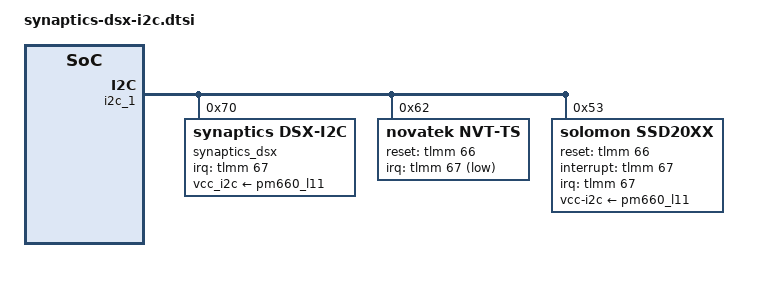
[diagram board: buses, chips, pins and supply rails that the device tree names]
/* Copyright (c) 2016-2018, The Linux Foundation. All rights reserved.
 *
 * This program is free software; you can redistribute it and/or modify
 * it under the terms of the GNU General Public License version 2 and
 * only version 2 as published by the Free Software Foundation.
 *
 * This program is distributed in the hope that it will be useful,
 * but WITHOUT ANY WARRANTY; without even the implied warranty of
 * MERCHANTABILITY or FITNESS FOR A PARTICULAR PURPOSE.  See the
 * GNU General Public License for more details.
 */

&i2c_1{
	status = "ok";
	synaptics_dsx@70 {
		compatible = "synaptics,dsx-i2c";
		reg = <0x70>;
		interrupt-parent = <&tlmm>;
		interrupts = <67 0x2008>;
		vcc_i2c-supply= <&pm660_l11>;
		pinctrl-names = "pmx_ts_active", "pmx_ts_suspend";
		pinctrl-0 = <&ts_active>;
		pinctrl-1 = <&ts_int_suspend &ts_reset_suspend>;
		synaptics,ub-i2c-addr = <0x2c>;
		synaptics,irq-gpio = <&tlmm 67 0x2008>; /* IRQF_ONESHOT | IRQF_TRIGGER_LOW */
		synaptics,irq-on-state = <0>;
		synaptics,power-delay-ms = <200>;
		synaptics,reset-delay-ms = <200>;
		synaptics,reset-on-state = <0>;
		synaptics,reset-active-ms = <20>;
		/* uncomment and update line below as appropriate if there are 0D buttons */
		synaptics,cap-button-codes = <139 172 158>;
	};

	/* Novatek device tree node */
	novatek@62 {
		compatible = "novatek,NVT-ts";
		reg = <0x62>;
		status = "ok";

		novatek,reset-gpio = <&tlmm 66 0x00>;
		novatek,irq-gpio = <&tlmm 67 0x2001>;

		/* MP Config*/
		IC_X_CFG_SIZE = <18>;
		IC_Y_CFG_SIZE = <32>;
		IC_KEY_CFG_SIZE = <4>;
		X_Channel = <18>;
		Y_Channel = <32>;
		AIN_X = <17 16 15 14 13 12 11 10 9 8 7 6 5 4 3 2 1 0>;
		AIN_Y = <31 30 29 28 27 26 25 24 23 22 21 20 19 18 17 16 15 14 13 12 11 10 9 8 7 6 5 4 3 2 1 0>;
		AIN_KEY = <0 1 2 0xFF>;

		novatek-mp-criteria-nvtpid@0 {
			#address-cells = <1>;
			#size-cells = <0>;
			compatible = "novatek-mp-criteria-nvtpid";

			/* MP Criteria */
			PS_Config_Lmt_Short_Rawdata_P = <
				20000 20000 20000 20000 20000 20000 20000 20000 20000 20000 20000 20000 20000 20000 20000 20000 20000 20000
				20000 20000 20000 20000 20000 20000 20000 20000 20000 20000 20000 20000 20000 20000 20000 20000 20000 20000
				20000 20000 20000 20000 20000 20000 20000 20000 20000 20000 20000 20000 20000 20000 20000 20000 20000 20000
				20000 20000 20000 20000 20000 20000 20000 20000 20000 20000 20000 20000 20000 20000 20000 20000 20000 20000
				20000 20000 20000 20000 20000 20000 20000 20000 20000 20000 20000 20000 20000 20000 20000 20000 20000 20000
				20000 20000 20000 20000 20000 20000 20000 20000 20000 20000 20000 20000 20000 20000 20000 20000 20000 20000
				20000 20000 20000 20000 20000 20000 20000 20000 20000 20000 20000 20000 20000 20000 20000 20000 20000 20000
				20000 20000 20000 20000 20000 20000 20000 20000 20000 20000 20000 20000 20000 20000 20000 20000 20000 20000
				20000 20000 20000 20000 20000 20000 20000 20000 20000 20000 20000 20000 20000 20000 20000 20000 20000 20000
				20000 20000 20000 20000 20000 20000 20000 20000 20000 20000 20000 20000 20000 20000 20000 20000 20000 20000
				20000 20000 20000 20000 20000 20000 20000 20000 20000 20000 20000 20000 20000 20000 20000 20000 20000 20000
				20000 20000 20000 20000 20000 20000 20000 20000 20000 20000 20000 20000 20000 20000 20000 20000 20000 20000
				20000 20000 20000 20000 20000 20000 20000 20000 20000 20000 20000 20000 20000 20000 20000 20000 20000 20000
				20000 20000 20000 20000 20000 20000 20000 20000 20000 20000 20000 20000 20000 20000 20000 20000 20000 20000
				20000 20000 20000 20000 20000 20000 20000 20000 20000 20000 20000 20000 20000 20000 20000 20000 20000 20000
				20000 20000 20000 20000 20000 20000 20000 20000 20000 20000 20000 20000 20000 20000 20000 20000 20000 20000
				20000 20000 20000 20000 20000 20000 20000 20000 20000 20000 20000 20000 20000 20000 20000 20000 20000 20000
				20000 20000 20000 20000 20000 20000 20000 20000 20000 20000 20000 20000 20000 20000 20000 20000 20000 20000
				20000 20000 20000 20000 20000 20000 20000 20000 20000 20000 20000 20000 20000 20000 20000 20000 20000 20000
				20000 20000 20000 20000 20000 20000 20000 20000 20000 20000 20000 20000 20000 20000 20000 20000 20000 20000
				20000 20000 20000 20000 20000 20000 20000 20000 20000 20000 20000 20000 20000 20000 20000 20000 20000 20000
				20000 20000 20000 20000 20000 20000 20000 20000 20000 20000 20000 20000 20000 20000 20000 20000 20000 20000
				20000 20000 20000 20000 20000 20000 20000 20000 20000 20000 20000 20000 20000 20000 20000 20000 20000 20000
				20000 20000 20000 20000 20000 20000 20000 20000 20000 20000 20000 20000 20000 20000 20000 20000 20000 20000
				20000 20000 20000 20000 20000 20000 20000 20000 20000 20000 20000 20000 20000 20000 20000 20000 20000 20000
				20000 20000 20000 20000 20000 20000 20000 20000 20000 20000 20000 20000 20000 20000 20000 20000 20000 20000
				20000 20000 20000 20000 20000 20000 20000 20000 20000 20000 20000 20000 20000 20000 20000 20000 20000 20000
				20000 20000 20000 20000 20000 20000 20000 20000 20000 20000 20000 20000 20000 20000 20000 20000 20000 20000
				20000 20000 20000 20000 20000 20000 20000 20000 20000 20000 20000 20000 20000 20000 20000 20000 20000 20000
				20000 20000 20000 20000 20000 20000 20000 20000 20000 20000 20000 20000 20000 20000 20000 20000 20000 20000
				20000 20000 20000 20000 20000 20000 20000 20000 20000 20000 20000 20000 20000 20000 20000 20000 20000 20000
				20000 20000 20000 20000 20000 20000 20000 20000 20000 20000 20000 20000 20000 20000 20000 20000 20000 20000
				20000 20000 20000>;

			PS_Config_Lmt_Short_Rawdata_N = <
				11550 11550 11550 11550 11550 11550 11550 11550 11550 11550 11550 11550 11550 11550 11550 11550 11550 11550
				11550 11550 11550 11550 11550 11550 11550 11550 11550 11550 11550 11550 11550 11550 11550 11550 11550 11550
				11550 11550 11550 11550 11550 11550 11550 11550 11550 11550 11550 11550 11550 11550 11550 11550 11550 11550
				11550 11550 11550 11550 11550 11550 11550 11550 11550 11550 11550 11550 11550 11550 11550 11550 11550 11550
				11550 11550 11550 11550 11550 11550 11550 11550 11550 11550 11550 11550 11550 11550 11550 11550 11550 11550
				11550 11550 11550 11550 11550 11550 11550 11550 11550 11550 11550 11550 11550 11550 11550 11550 11550 11550
				11550 11550 11550 11550 11550 11550 11550 11550 11550 11550 11550 11550 11550 11550 11550 11550 11550 11550
				11550 11550 11550 11550 11550 11550 11550 11550 11550 11550 11550 11550 11550 11550 11550 11550 11550 11550
				11550 11550 11550 11550 11550 11550 11550 11550 11550 11550 11550 11550 11550 11550 11550 11550 11550 11550
				11550 11550 11550 11550 11550 11550 11550 11550 11550 11550 11550 11550 11550 11550 11550 11550 11550 11550
				11550 11550 11550 11550 11550 11550 11550 11550 11550 11550 11550 11550 11550 11550 11550 11550 11550 11550
				11550 11550 11550 11550 11550 11550 11550 11550 11550 11550 11550 11550 11550 11550 11550 11550 11550 11550
				11550 11550 11550 11550 11550 11550 11550 11550 11550 11550 11550 11550 11550 11550 11550 11550 11550 11550
				11550 11550 11550 11550 11550 11550 11550 11550 11550 11550 11550 11550 11550 11550 11550 11550 11550 11550
				11550 11550 11550 11550 11550 11550 11550 11550 11550 11550 11550 11550 11550 11550 11550 11550 11550 11550
				11550 11550 11550 11550 11550 11550 11550 11550 11550 11550 11550 11550 11550 11550 11550 11550 11550 11550
				11550 11550 11550 11550 11550 11550 11550 11550 11550 11550 11550 11550 11550 11550 11550 11550 11550 11550
				11550 11550 11550 11550 11550 11550 11550 11550 11550 11550 11550 11550 11550 11550 11550 11550 11550 11550
				11550 11550 11550 11550 11550 11550 11550 11550 11550 11550 11550 11550 11550 11550 11550 11550 11550 11550
				11550 11550 11550 11550 11550 11550 11550 11550 11550 11550 11550 11550 11550 11550 11550 11550 11550 11550
				11550 11550 11550 11550 11550 11550 11550 11550 11550 11550 11550 11550 11550 11550 11550 11550 11550 11550
				11550 11550 11550 11550 11550 11550 11550 11550 11550 11550 11550 11550 11550 11550 11550 11550 11550 11550
				11550 11550 11550 11550 11550 11550 11550 11550 11550 11550 11550 11550 11550 11550 11550 11550 11550 11550
				11550 11550 11550 11550 11550 11550 11550 11550 11550 11550 11550 11550 11550 11550 11550 11550 11550 11550
				11550 11550 11550 11550 11550 11550 11550 11550 11550 11550 11550 11550 11550 11550 11550 11550 11550 11550
				11550 11550 11550 11550 11550 11550 11550 11550 11550 11550 11550 11550 11550 11550 11550 11550 11550 11550
				11550 11550 11550 11550 11550 11550 11550 11550 11550 11550 11550 11550 11550 11550 11550 11550 11550 11550
				11550 11550 11550 11550 11550 11550 11550 11550 11550 11550 11550 11550 11550 11550 11550 11550 11550 11550
				11550 11550 11550 11550 11550 11550 11550 11550 11550 11550 11550 11550 11550 11550 11550 11550 11550 11550
				11550 11550 11550 11550 11550 11550 11550 11550 11550 11550 11550 11550 11550 11550 11550 11550 11550 11550
				11550 11550 11550 11550 11550 11550 11550 11550 11550 11550 11550 11550 11550 11550 11550 11550 11550 11550
				11550 11550 11550 11550 11550 11550 11550 11550 11550 11550 11550 11550 11550 11550 11550 11550 11550 11550
				11550 11550 11550>;

			PS_Config_Lmt_Short_Diff_P = <
				6300 6300 6300 6300 6300 6300 6300 6300 6300 6300 6300 6300 6300 6300 6300 6300 6300 6300
				6300 6300 6300 6300 6300 6300 6300 6300 6300 6300 6300 6300 6300 6300 6300 6300 6300 6300
				6300 6300 6300 6300 6300 6300 6300 6300 6300 6300 6300 6300 6300 6300 6300 6300 6300 6300
				6300 6300 6300 6300 6300 6300 6300 6300 6300 6300 6300 6300 6300 6300 6300 6300 6300 6300
				6300 6300 6300 6300 6300 6300 6300 6300 6300 6300 6300 6300 6300 6300 6300 6300 6300 6300
				6300 6300 6300 6300 6300 6300 6300 6300 6300 6300 6300 6300 6300 6300 6300 6300 6300 6300
				6300 6300 6300 6300 6300 6300 6300 6300 6300 6300 6300 6300 6300 6300 6300 6300 6300 6300
				6300 6300 6300 6300 6300 6300 6300 6300 6300 6300 6300 6300 6300 6300 6300 6300 6300 6300
				6300 6300 6300 6300 6300 6300 6300 6300 6300 6300 6300 6300 6300 6300 6300 6300 6300 6300
				6300 6300 6300 6300 6300 6300 6300 6300 6300 6300 6300 6300 6300 6300 6300 6300 6300 6300
				6300 6300 6300 6300 6300 6300 6300 6300 6300 6300 6300 6300 6300 6300 6300 6300 6300 6300
				6300 6300 6300 6300 6300 6300 6300 6300 6300 6300 6300 6300 6300 6300 6300 6300 6300 6300
				6300 6300 6300 6300 6300 6300 6300 6300 6300 6300 6300 6300 6300 6300 6300 6300 6300 6300
				6300 6300 6300 6300 6300 6300 6300 6300 6300 6300 6300 6300 6300 6300 6300 6300 6300 6300
				6300 6300 6300 6300 6300 6300 6300 6300 6300 6300 6300 6300 6300 6300 6300 6300 6300 6300
				6300 6300 6300 6300 6300 6300 6300 6300 6300 6300 6300 6300 6300 6300 6300 6300 6300 6300
				6300 6300 6300 6300 6300 6300 6300 6300 6300 6300 6300 6300 6300 6300 6300 6300 6300 6300
				6300 6300 6300 6300 6300 6300 6300 6300 6300 6300 6300 6300 6300 6300 6300 6300 6300 6300
				6300 6300 6300 6300 6300 6300 6300 6300 6300 6300 6300 6300 6300 6300 6300 6300 6300 6300
				6300 6300 6300 6300 6300 6300 6300 6300 6300 6300 6300 6300 6300 6300 6300 6300 6300 6300
				6300 6300 6300 6300 6300 6300 6300 6300 6300 6300 6300 6300 6300 6300 6300 6300 6300 6300
				6300 6300 6300 6300 6300 6300 6300 6300 6300 6300 6300 6300 6300 6300 6300 6300 6300 6300
				6300 6300 6300 6300 6300 6300 6300 6300 6300 6300 6300 6300 6300 6300 6300 6300 6300 6300
				6300 6300 6300 6300 6300 6300 6300 6300 6300 6300 6300 6300 6300 6300 6300 6300 6300 6300
				6300 6300 6300 6300 6300 6300 6300 6300 6300 6300 6300 6300 6300 6300 6300 6300 6300 6300
				6300 6300 6300 6300 6300 6300 6300 6300 6300 6300 6300 6300 6300 6300 6300 6300 6300 6300
				6300 6300 6300 6300 6300 6300 6300 6300 6300 6300 6300 6300 6300 6300 6300 6300 6300 6300
				6300 6300 6300 6300 6300 6300 6300 6300 6300 6300 6300 6300 6300 6300 6300 6300 6300 6300
				6300 6300 6300 6300 6300 6300 6300 6300 6300 6300 6300 6300 6300 6300 6300 6300 6300 6300
				6300 6300 6300 6300 6300 6300 6300 6300 6300 6300 6300 6300 6300 6300 6300 6300 6300 6300
				6300 6300 6300 6300 6300 6300 6300 6300 6300 6300 6300 6300 6300 6300 6300 6300 6300 6300
				6300 6300 6300 6300 6300 6300 6300 6300 6300 6300 6300 6300 6300 6300 6300 6300 6300 6300
				6300 6300 6300>;

			PS_Config_Lmt_Short_Diff_N = <
				0 0 0 0 0 0 0 0 0 0 0 0 0 0 0 0 0
				0 0 0 0 0 0 0 0 0 0 0 0 0 0 0 0 0
				0 0 0 0 0 0 0 0 0 0 0 0 0 0 0 0 0
				0 0 0 0 0 0 0 0 0 0 0 0 0 0 0 0 0
				0 0 0 0 0 0 0 0 0 0 0 0 0 0 0 0 0
				0 0 0 0 0 0 0 0 0 0 0 0 0 0 0 0 0
				0 0 0 0 0 0 0 0 0 0 0 0 0 0 0 0 0
				0 0 0 0 0 0 0 0 0 0 0 0 0 0 0 0 0
				0 0 0 0 0 0 0 0 0 0 0 0 0 0 0 0 0
				0 0 0 0 0 0 0 0 0 0 0 0 0 0 0 0 0
				0 0 0 0 0 0 0 0 0 0 0 0 0 0 0 0 0
				0 0 0 0 0 0 0 0 0 0 0 0 0 0 0 0 0
				0 0 0 0 0 0 0 0 0 0 0 0 0 0 0 0 0
				0 0 0 0 0 0 0 0 0 0 0 0 0 0 0 0 0
				0 0 0 0 0 0 0 0 0 0 0 0 0 0 0 0 0
				0 0 0 0 0 0 0 0 0 0 0 0 0 0 0 0 0
				0 0 0 0 0 0 0 0 0 0 0 0 0 0 0 0 0
				0 0 0 0 0 0 0 0 0 0 0 0 0 0 0 0 0
				0 0 0 0 0 0 0 0 0 0 0 0 0 0 0 0 0
				0 0 0 0 0 0 0 0 0 0 0 0 0 0 0 0 0
				0 0 0 0 0 0 0 0 0 0 0 0 0 0 0 0 0
				0 0 0 0 0 0 0 0 0 0 0 0 0 0 0 0 0
				0 0 0 0 0 0 0 0 0 0 0 0 0 0 0 0 0
				0 0 0 0 0 0 0 0 0 0 0 0 0 0 0 0 0
				0 0 0 0 0 0 0 0 0 0 0 0 0 0 0 0 0
				0 0 0 0 0 0 0 0 0 0 0 0 0 0 0 0 0
				0 0 0 0 0 0 0 0 0 0 0 0 0 0 0 0 0
				0 0 0 0 0 0 0 0 0 0 0 0 0 0 0 0 0
				0 0 0 0 0 0 0 0 0 0 0 0 0 0 0 0 0
				0 0 0 0 0 0 0 0 0 0 0 0 0 0 0 0 0
				0 0 0 0 0 0 0 0 0 0 0 0 0 0 0 0 0
				0 0 0 0 0 0 0 0 0 0 0 0 0 0 0 0 0
				0 0 0 0 0 0 0 0 0 0 0 0 0 0 0 0 0
				0 0 0 0 0 0 0 0 0 0 0 0 0 0 0 0 0
				0>;

			PS_Config_Lmt_Short_Base_P = <
				2000 2000 2000 2000 2000 2000 2000 2000 2000 2000 2000 2000 2000 2000 2000 2000 2000 2000
				2000 2000 2000 2000 2000 2000 2000 2000 2000 2000 2000 2000 2000 2000 2000 2000 2000 2000
				2000 2000 2000 2000 2000 2000 2000 2000 2000 2000 2000 2000 2000 2000 2000 2000 2000 2000
				2000 2000 2000 2000 2000 2000 2000 2000 2000 2000 2000 2000 2000 2000 2000 2000 2000 2000
				2000 2000 2000 2000 2000 2000 2000 2000 2000 2000 2000 2000 2000 2000 2000 2000 2000 2000
				2000 2000 2000 2000 2000 2000 2000 2000 2000 2000 2000 2000 2000 2000 2000 2000 2000 2000
				2000 2000 2000 2000 2000 2000 2000 2000 2000 2000 2000 2000 2000 2000 2000 2000 2000 2000
				2000 2000 2000 2000 2000 2000 2000 2000 2000 2000 2000 2000 2000 2000 2000 2000 2000 2000
				2000 2000 2000 2000 2000 2000 2000 2000 2000 2000 2000 2000 2000 2000 2000 2000 2000 2000
				2000 2000 2000 2000 2000 2000 2000 2000 2000 2000 2000 2000 2000 2000 2000 2000 2000 2000
				2000 2000 2000 2000 2000 2000 2000 2000 2000 2000 2000 2000 2000 2000 2000 2000 2000 2000
				2000 2000 2000 2000 2000 2000 2000 2000 2000 2000 2000 2000 2000 2000 2000 2000 2000 2000
				2000 2000 2000 2000 2000 2000 2000 2000 2000 2000 2000 2000 2000 2000 2000 2000 2000 2000
				2000 2000 2000 2000 2000 2000 2000 2000 2000 2000 2000 2000 2000 2000 2000 2000 2000 2000
				2000 2000 2000 2000 2000 2000 2000 2000 2000 2000 2000 2000 2000 2000 2000 2000 2000 2000
				2000 2000 2000 2000 2000 2000 2000 2000 2000 2000 2000 2000 2000 2000 2000 2000 2000 2000
				2000 2000 2000 2000 2000 2000 2000 2000 2000 2000 2000 2000 2000 2000 2000 2000 2000 2000
				2000 2000 2000 2000 2000 2000 2000 2000 2000 2000 2000 2000 2000 2000 2000 2000 2000 2000
				2000 2000 2000 2000 2000 2000 2000 2000 2000 2000 2000 2000 2000 2000 2000 2000 2000 2000
				2000 2000 2000 2000 2000 2000 2000 2000 2000 2000 2000 2000 2000 2000 2000 2000 2000 2000
				2000 2000 2000 2000 2000 2000 2000 2000 2000 2000 2000 2000 2000 2000 2000 2000 2000 2000
				2000 2000 2000 2000 2000 2000 2000 2000 2000 2000 2000 2000 2000 2000 2000 2000 2000 2000
				2000 2000 2000 2000 2000 2000 2000 2000 2000 2000 2000 2000 2000 2000 2000 2000 2000 2000
				2000 2000 2000 2000 2000 2000 2000 2000 2000 2000 2000 2000 2000 2000 2000 2000 2000 2000
				2000 2000 2000 2000 2000 2000 2000 2000 2000 2000 2000 2000 2000 2000 2000 2000 2000 2000
				2000 2000 2000 2000 2000 2000 2000 2000 2000 2000 2000 2000 2000 2000 2000 2000 2000 2000
				2000 2000 2000 2000 2000 2000 2000 2000 2000 2000 2000 2000 2000 2000 2000 2000 2000 2000
				2000 2000 2000 2000 2000 2000 2000 2000 2000 2000 2000 2000 2000 2000 2000 2000 2000 2000
				2000 2000 2000 2000 2000 2000 2000 2000 2000 2000 2000 2000 2000 2000 2000 2000 2000 2000
				2000 2000 2000 2000 2000 2000 2000 2000 2000 2000 2000 2000 2000 2000 2000 2000 2000 2000
				2000 2000 2000 2000 2000 2000 2000 2000 2000 2000 2000 2000 2000 2000 2000 2000 2000 2000
				2000 2000 2000 2000 2000 2000 2000 2000 2000 2000 2000 2000 2000 2000 2000 2000 2000 2000
				2000 2000 2000>;

			PS_Config_Lmt_Short_Base_N = <
				0xfffff830 0xfffff830 0xfffff830 0xfffff830 0xfffff830 0xfffff830 0xfffff830 0xfffff830 0xfffff830 0xfffff830 0xfffff830 0xfffff830 0xfffff830 0xfffff830 0xfffff830 0xfffff830 0xfffff830 0xfffff830
				0xfffff830 0xfffff830 0xfffff830 0xfffff830 0xfffff830 0xfffff830 0xfffff830 0xfffff830 0xfffff830 0xfffff830 0xfffff830 0xfffff830 0xfffff830 0xfffff830 0xfffff830 0xfffff830 0xfffff830 0xfffff830
				0xfffff830 0xfffff830 0xfffff830 0xfffff830 0xfffff830 0xfffff830 0xfffff830 0xfffff830 0xfffff830 0xfffff830 0xfffff830 0xfffff830 0xfffff830 0xfffff830 0xfffff830 0xfffff830 0xfffff830 0xfffff830
				0xfffff830 0xfffff830 0xfffff830 0xfffff830 0xfffff830 0xfffff830 0xfffff830 0xfffff830 0xfffff830 0xfffff830 0xfffff830 0xfffff830 0xfffff830 0xfffff830 0xfffff830 0xfffff830 0xfffff830 0xfffff830
				0xfffff830 0xfffff830 0xfffff830 0xfffff830 0xfffff830 0xfffff830 0xfffff830 0xfffff830 0xfffff830 0xfffff830 0xfffff830 0xfffff830 0xfffff830 0xfffff830 0xfffff830 0xfffff830 0xfffff830 0xfffff830
				0xfffff830 0xfffff830 0xfffff830 0xfffff830 0xfffff830 0xfffff830 0xfffff830 0xfffff830 0xfffff830 0xfffff830 0xfffff830 0xfffff830 0xfffff830 0xfffff830 0xfffff830 0xfffff830 0xfffff830 0xfffff830
				0xfffff830 0xfffff830 0xfffff830 0xfffff830 0xfffff830 0xfffff830 0xfffff830 0xfffff830 0xfffff830 0xfffff830 0xfffff830 0xfffff830 0xfffff830 0xfffff830 0xfffff830 0xfffff830 0xfffff830 0xfffff830
				0xfffff830 0xfffff830 0xfffff830 0xfffff830 0xfffff830 0xfffff830 0xfffff830 0xfffff830 0xfffff830 0xfffff830 0xfffff830 0xfffff830 0xfffff830 0xfffff830 0xfffff830 0xfffff830 0xfffff830 0xfffff830
				0xfffff830 0xfffff830 0xfffff830 0xfffff830 0xfffff830 0xfffff830 0xfffff830 0xfffff830 0xfffff830 0xfffff830 0xfffff830 0xfffff830 0xfffff830 0xfffff830 0xfffff830 0xfffff830 0xfffff830 0xfffff830
				0xfffff830 0xfffff830 0xfffff830 0xfffff830 0xfffff830 0xfffff830 0xfffff830 0xfffff830 0xfffff830 0xfffff830 0xfffff830 0xfffff830 0xfffff830 0xfffff830 0xfffff830 0xfffff830 0xfffff830 0xfffff830
				0xfffff830 0xfffff830 0xfffff830 0xfffff830 0xfffff830 0xfffff830 0xfffff830 0xfffff830 0xfffff830 0xfffff830 0xfffff830 0xfffff830 0xfffff830 0xfffff830 0xfffff830 0xfffff830 0xfffff830 0xfffff830
				0xfffff830 0xfffff830 0xfffff830 0xfffff830 0xfffff830 0xfffff830 0xfffff830 0xfffff830 0xfffff830 0xfffff830 0xfffff830 0xfffff830 0xfffff830 0xfffff830 0xfffff830 0xfffff830 0xfffff830 0xfffff830
				0xfffff830 0xfffff830 0xfffff830 0xfffff830 0xfffff830 0xfffff830 0xfffff830 0xfffff830 0xfffff830 0xfffff830 0xfffff830 0xfffff830 0xfffff830 0xfffff830 0xfffff830 0xfffff830 0xfffff830 0xfffff830
				0xfffff830 0xfffff830 0xfffff830 0xfffff830 0xfffff830 0xfffff830 0xfffff830 0xfffff830 0xfffff830 0xfffff830 0xfffff830 0xfffff830 0xfffff830 0xfffff830 0xfffff830 0xfffff830 0xfffff830 0xfffff830
				0xfffff830 0xfffff830 0xfffff830 0xfffff830 0xfffff830 0xfffff830 0xfffff830 0xfffff830 0xfffff830 0xfffff830 0xfffff830 0xfffff830 0xfffff830 0xfffff830 0xfffff830 0xfffff830 0xfffff830 0xfffff830
				0xfffff830 0xfffff830 0xfffff830 0xfffff830 0xfffff830 0xfffff830 0xfffff830 0xfffff830 0xfffff830 0xfffff830 0xfffff830 0xfffff830 0xfffff830 0xfffff830 0xfffff830 0xfffff830 0xfffff830 0xfffff830
				0xfffff830 0xfffff830 0xfffff830 0xfffff830 0xfffff830 0xfffff830 0xfffff830 0xfffff830 0xfffff830 0xfffff830 0xfffff830 0xfffff830 0xfffff830 0xfffff830 0xfffff830 0xfffff830 0xfffff830 0xfffff830
				0xfffff830 0xfffff830 0xfffff830 0xfffff830 0xfffff830 0xfffff830 0xfffff830 0xfffff830 0xfffff830 0xfffff830 0xfffff830 0xfffff830 0xfffff830 0xfffff830 0xfffff830 0xfffff830 0xfffff830 0xfffff830
				0xfffff830 0xfffff830 0xfffff830 0xfffff830 0xfffff830 0xfffff830 0xfffff830 0xfffff830 0xfffff830 0xfffff830 0xfffff830 0xfffff830 0xfffff830 0xfffff830 0xfffff830 0xfffff830 0xfffff830 0xfffff830
				0xfffff830 0xfffff830 0xfffff830 0xfffff830 0xfffff830 0xfffff830 0xfffff830 0xfffff830 0xfffff830 0xfffff830 0xfffff830 0xfffff830 0xfffff830 0xfffff830 0xfffff830 0xfffff830 0xfffff830 0xfffff830
				0xfffff830 0xfffff830 0xfffff830 0xfffff830 0xfffff830 0xfffff830 0xfffff830 0xfffff830 0xfffff830 0xfffff830 0xfffff830 0xfffff830 0xfffff830 0xfffff830 0xfffff830 0xfffff830 0xfffff830 0xfffff830
				0xfffff830 0xfffff830 0xfffff830 0xfffff830 0xfffff830 0xfffff830 0xfffff830 0xfffff830 0xfffff830 0xfffff830 0xfffff830 0xfffff830 0xfffff830 0xfffff830 0xfffff830 0xfffff830 0xfffff830 0xfffff830
				0xfffff830 0xfffff830 0xfffff830 0xfffff830 0xfffff830 0xfffff830 0xfffff830 0xfffff830 0xfffff830 0xfffff830 0xfffff830 0xfffff830 0xfffff830 0xfffff830 0xfffff830 0xfffff830 0xfffff830 0xfffff830
				0xfffff830 0xfffff830 0xfffff830 0xfffff830 0xfffff830 0xfffff830 0xfffff830 0xfffff830 0xfffff830 0xfffff830 0xfffff830 0xfffff830 0xfffff830 0xfffff830 0xfffff830 0xfffff830 0xfffff830 0xfffff830
				0xfffff830 0xfffff830 0xfffff830 0xfffff830 0xfffff830 0xfffff830 0xfffff830 0xfffff830 0xfffff830 0xfffff830 0xfffff830 0xfffff830 0xfffff830 0xfffff830 0xfffff830 0xfffff830 0xfffff830 0xfffff830
				0xfffff830 0xfffff830 0xfffff830 0xfffff830 0xfffff830 0xfffff830 0xfffff830 0xfffff830 0xfffff830 0xfffff830 0xfffff830 0xfffff830 0xfffff830 0xfffff830 0xfffff830 0xfffff830 0xfffff830 0xfffff830
				0xfffff830 0xfffff830 0xfffff830 0xfffff830 0xfffff830 0xfffff830 0xfffff830 0xfffff830 0xfffff830 0xfffff830 0xfffff830 0xfffff830 0xfffff830 0xfffff830 0xfffff830 0xfffff830 0xfffff830 0xfffff830
				0xfffff830 0xfffff830 0xfffff830 0xfffff830 0xfffff830 0xfffff830 0xfffff830 0xfffff830 0xfffff830 0xfffff830 0xfffff830 0xfffff830 0xfffff830 0xfffff830 0xfffff830 0xfffff830 0xfffff830 0xfffff830
				0xfffff830 0xfffff830 0xfffff830 0xfffff830 0xfffff830 0xfffff830 0xfffff830 0xfffff830 0xfffff830 0xfffff830 0xfffff830 0xfffff830 0xfffff830 0xfffff830 0xfffff830 0xfffff830 0xfffff830 0xfffff830
				0xfffff830 0xfffff830 0xfffff830 0xfffff830 0xfffff830 0xfffff830 0xfffff830 0xfffff830 0xfffff830 0xfffff830 0xfffff830 0xfffff830 0xfffff830 0xfffff830 0xfffff830 0xfffff830 0xfffff830 0xfffff830
				0xfffff830 0xfffff830 0xfffff830 0xfffff830 0xfffff830 0xfffff830 0xfffff830 0xfffff830 0xfffff830 0xfffff830 0xfffff830 0xfffff830 0xfffff830 0xfffff830 0xfffff830 0xfffff830 0xfffff830 0xfffff830
				0xfffff830 0xfffff830 0xfffff830 0xfffff830 0xfffff830 0xfffff830 0xfffff830 0xfffff830 0xfffff830 0xfffff830 0xfffff830 0xfffff830 0xfffff830 0xfffff830 0xfffff830 0xfffff830 0xfffff830 0xfffff830
				0xfffff830 0xfffff830 0xfffff830>;

			PS_Config_Lmt_Open_Rawdata_P = <
				13000 13000 13000 13000 13000 13000 13000 13000 13000 13000 13000 13000 13000 13000 13000 13000 13000 13000
				13000 13000 13000 13000 13000 13000 13000 13000 13000 13000 13000 13000 13000 13000 13000 13000 13000 13000
				13000 13000 13000 13000 13000 13000 13000 13000 13000 13000 13000 13000 13000 13000 13000 13000 13000 13000
				13000 13000 13000 13000 13000 13000 13000 13000 13000 13000 13000 13000 13000 13000 13000 13000 13000 13000
				13000 13000 13000 13000 13000 13000 13000 13000 13000 13000 13000 13000 13000 13000 13000 13000 13000 13000
				13000 13000 13000 13000 13000 13000 13000 13000 13000 13000 13000 13000 13000 13000 13000 13000 13000 13000
				13000 13000 13000 13000 13000 13000 13000 13000 13000 13000 13000 13000 13000 13000 13000 13000 13000 13000
				13000 13000 13000 13000 13000 13000 13000 13000 13000 13000 13000 13000 13000 13000 13000 13000 13000 13000
				13000 13000 13000 13000 13000 13000 13000 13000 13000 13000 13000 13000 13000 13000 13000 13000 13000 13000
				13000 13000 13000 13000 13000 13000 13000 13000 13000 13000 13000 13000 13000 13000 13000 13000 13000 13000
				13000 13000 13000 13000 13000 13000 13000 13000 13000 13000 13000 13000 13000 13000 13000 13000 13000 13000
				13000 13000 13000 13000 13000 13000 13000 13000 13000 13000 13000 13000 13000 13000 13000 13000 13000 13000
				13000 13000 13000 13000 13000 13000 13000 13000 13000 13000 13000 13000 13000 13000 13000 13000 13000 13000
				13000 13000 13000 13000 13000 13000 13000 13000 13000 13000 13000 13000 13000 13000 13000 13000 13000 13000
				13000 13000 13000 13000 13000 13000 13000 13000 13000 13000 13000 13000 13000 13000 13000 13000 13000 13000
				13000 13000 13000 13000 13000 13000 13000 13000 13000 13000 13000 13000 13000 13000 13000 13000 13000 13000
				13000 13000 13000 13000 13000 13000 13000 13000 13000 13000 13000 13000 13000 13000 13000 13000 13000 13000
				13000 13000 13000 13000 13000 13000 13000 13000 13000 13000 13000 13000 13000 13000 13000 13000 13000 13000
				13000 13000 13000 13000 13000 13000 13000 13000 13000 13000 13000 13000 13000 13000 13000 13000 13000 13000
				13000 13000 13000 13000 13000 13000 13000 13000 13000 13000 13000 13000 13000 13000 13000 13000 13000 13000
				13000 13000 13000 13000 13000 13000 13000 13000 13000 13000 13000 13000 13000 13000 13000 13000 13000 13000
				13000 13000 13000 13000 13000 13000 13000 13000 13000 13000 13000 13000 13000 13000 13000 13000 13000 13000
				13000 13000 13000 13000 13000 13000 13000 13000 13000 13000 13000 13000 13000 13000 13000 13000 13000 13000
				13000 13000 13000 13000 13000 13000 13000 13000 13000 13000 13000 13000 13000 13000 13000 13000 13000 13000
				13000 13000 13000 13000 13000 13000 13000 13000 13000 13000 13000 13000 13000 13000 13000 13000 13000 13000
				13000 13000 13000 13000 13000 13000 13000 13000 13000 13000 13000 13000 13000 13000 13000 13000 13000 13000
				13000 13000 13000 13000 13000 13000 13000 13000 13000 13000 13000 13000 13000 13000 13000 13000 13000 13000
				13000 13000 13000 13000 13000 13000 13000 13000 13000 13000 13000 13000 13000 13000 13000 13000 13000 13000
				13000 13000 13000 13000 13000 13000 13000 13000 13000 13000 13000 13000 13000 13000 13000 13000 13000 13000
				13000 13000 13000 13000 13000 13000 13000 13000 13000 13000 13000 13000 13000 13000 13000 13000 13000 13000
				13000 13000 13000 13000 13000 13000 13000 13000 13000 13000 13000 13000 13000 13000 13000 13000 13000 13000
				13000 13000 13000 13000 13000 13000 13000 13000 13000 13000 13000 13000 13000 13000 13000 13000 13000 13000
				13000 13000 13000>;

			PS_Config_Lmt_Open_Rawdata_N = <
				6500 6500 6500 6500 6500 6500 6500 6500 6500 6500 6500 6500 6500 6500 6500 6500 6500 6500
				6500 6500 6500 6500 6500 6500 6500 6500 6500 6500 6500 6500 6500 6500 6500 6500 6500 6500
				6500 6500 6500 6500 6500 6500 6500 6500 6500 6500 6500 6500 6500 6500 6500 6500 6500 6500
				6500 6500 6500 6500 6500 6500 6500 6500 6500 6500 6500 6500 6500 6500 6500 6500 6500 6500
				6500 6500 6500 6500 6500 6500 6500 6500 6500 6500 6500 6500 6500 6500 6500 6500 6500 6500
				6500 6500 6500 6500 6500 6500 6500 6500 6500 6500 6500 6500 6500 6500 6500 6500 6500 6500
				6500 6500 6500 6500 6500 6500 6500 6500 6500 6500 6500 6500 6500 6500 6500 6500 6500 6500
				6500 6500 6500 6500 6500 6500 6500 6500 6500 6500 6500 6500 6500 6500 6500 6500 6500 6500
				6500 6500 6500 6500 6500 6500 6500 6500 6500 6500 6500 6500 6500 6500 6500 6500 6500 6500
				6500 6500 6500 6500 6500 6500 6500 6500 6500 6500 6500 6500 6500 6500 6500 6500 6500 6500
				6500 6500 6500 6500 6500 6500 6500 6500 6500 6500 6500 6500 6500 6500 6500 6500 6500 6500
				6500 6500 6500 6500 6500 6500 6500 6500 6500 6500 6500 6500 6500 6500 6500 6500 6500 6500
				6500 6500 6500 6500 6500 6500 6500 6500 6500 6500 6500 6500 6500 6500 6500 6500 6500 6500
				6500 6500 6500 6500 6500 6500 6500 6500 6500 6500 6500 6500 6500 6500 6500 6500 6500 6500
				6500 6500 6500 6500 6500 6500 6500 6500 6500 6500 6500 6500 6500 6500 6500 6500 6500 6500
				6500 6500 6500 6500 6500 6500 6500 6500 6500 6500 6500 6500 6500 6500 6500 6500 6500 6500
				6500 6500 6500 6500 6500 6500 6500 6500 6500 6500 6500 6500 6500 6500 6500 6500 6500 6500
				6500 6500 6500 6500 6500 6500 6500 6500 6500 6500 6500 6500 6500 6500 6500 6500 6500 6500
				6500 6500 6500 6500 6500 6500 6500 6500 6500 6500 6500 6500 6500 6500 6500 6500 6500 6500
				6500 6500 6500 6500 6500 6500 6500 6500 6500 6500 6500 6500 6500 6500 6500 6500 6500 6500
				6500 6500 6500 6500 6500 6500 6500 6500 6500 6500 6500 6500 6500 6500 6500 6500 6500 6500
				6500 6500 6500 6500 6500 6500 6500 6500 6500 6500 6500 6500 6500 6500 6500 6500 6500 6500
				6500 6500 6500 6500 6500 6500 6500 6500 6500 6500 6500 6500 6500 6500 6500 6500 6500 6500
				6500 6500 6500 6500 6500 6500 6500 6500 6500 6500 6500 6500 6500 6500 6500 6500 6500 6500
				6500 6500 6500 6500 6500 6500 6500 6500 6500 6500 6500 6500 6500 6500 6500 6500 6500 6500
				6500 6500 6500 6500 6500 6500 6500 6500 6500 6500 6500 6500 6500 6500 6500 6500 6500 6500
				6500 6500 6500 6500 6500 6500 6500 6500 6500 6500 6500 6500 6500 6500 6500 6500 6500 6500
				6500 6500 6500 6500 6500 6500 6500 6500 6500 6500 6500 6500 6500 6500 6500 6500 6500 6500
				6500 6500 6500 6500 6500 6500 6500 6500 6500 6500 6500 6500 6500 6500 6500 6500 6500 6500
				6500 6500 6500 6500 6500 6500 6500 6500 6500 6500 6500 6500 6500 6500 6500 6500 6500 6500
				6500 6500 6500 6500 6500 6500 6500 6500 6500 6500 6500 6500 6500 6500 6500 6500 6500 6500
				6500 6500 6500 6500 6500 6500 6500 6500 6500 6500 6500 6500 6500 6500 6500 6500 6500 6500
				6500 6500 6500>;
			PS_Config_Lmt_FW_Rawdata_P = <
				2000 2000 2000 2000 2000 2000 2000 2000 2000 2000 2000 2000 2000 2000 2000 2000 2000 2000
				2000 2000 2000 2000 2000 2000 2000 2000 2000 2000 2000 2000 2000 2000 2000 2000 2000 2000
				2000 2000 2000 2000 2000 2000 2000 2000 2000 2000 2000 2000 2000 2000 2000 2000 2000 2000
				2000 2000 2000 2000 2000 2000 2000 2000 2000 2000 2000 2000 2000 2000 2000 2000 2000 2000
				2000 2000 2000 2000 2000 2000 2000 2000 2000 2000 2000 2000 2000 2000 2000 2000 2000 2000
				2000 2000 2000 2000 2000 2000 2000 2000 2000 2000 2000 2000 2000 2000 2000 2000 2000 2000
				2000 2000 2000 2000 2000 2000 2000 2000 2000 2000 2000 2000 2000 2000 2000 2000 2000 2000
				2000 2000 2000 2000 2000 2000 2000 2000 2000 2000 2000 2000 2000 2000 2000 2000 2000 2000
				2000 2000 2000 2000 2000 2000 2000 2000 2000 2000 2000 2000 2000 2000 2000 2000 2000 2000
				2000 2000 2000 2000 2000 2000 2000 2000 2000 2000 2000 2000 2000 2000 2000 2000 2000 2000
				2000 2000 2000 2000 2000 2000 2000 2000 2000 2000 2000 2000 2000 2000 2000 2000 2000 2000
				2000 2000 2000 2000 2000 2000 2000 2000 2000 2000 2000 2000 2000 2000 2000 2000 2000 2000
				2000 2000 2000 2000 2000 2000 2000 2000 2000 2000 2000 2000 2000 2000 2000 2000 2000 2000
				2000 2000 2000 2000 2000 2000 2000 2000 2000 2000 2000 2000 2000 2000 2000 2000 2000 2000
				2000 2000 2000 2000 2000 2000 2000 2000 2000 2000 2000 2000 2000 2000 2000 2000 2000 2000
				2000 2000 2000 2000 2000 2000 2000 2000 2000 2000 2000 2000 2000 2000 2000 2000 2000 2000
				2000 2000 2000 2000 2000 2000 2000 2000 2000 2000 2000 2000 2000 2000 2000 2000 2000 2000
				2000 2000 2000 2000 2000 2000 2000 2000 2000 2000 2000 2000 2000 2000 2000 2000 2000 2000
				2000 2000 2000 2000 2000 2000 2000 2000 2000 2000 2000 2000 2000 2000 2000 2000 2000 2000
				2000 2000 2000 2000 2000 2000 2000 2000 2000 2000 2000 2000 2000 2000 2000 2000 2000 2000
				2000 2000 2000 2000 2000 2000 2000 2000 2000 2000 2000 2000 2000 2000 2000 2000 2000 2000
				2000 2000 2000 2000 2000 2000 2000 2000 2000 2000 2000 2000 2000 2000 2000 2000 2000 2000
				2000 2000 2000 2000 2000 2000 2000 2000 2000 2000 2000 2000 2000 2000 2000 2000 2000 2000
				2000 2000 2000 2000 2000 2000 2000 2000 2000 2000 2000 2000 2000 2000 2000 2000 2000 2000
				2000 2000 2000 2000 2000 2000 2000 2000 2000 2000 2000 2000 2000 2000 2000 2000 2000 2000
				2000 2000 2000 2000 2000 2000 2000 2000 2000 2000 2000 2000 2000 2000 2000 2000 2000 2000
				2000 2000 2000 2000 2000 2000 2000 2000 2000 2000 2000 2000 2000 2000 2000 2000 2000 2000
				2000 2000 2000 2000 2000 2000 2000 2000 2000 2000 2000 2000 2000 2000 2000 2000 2000 2000
				2000 2000 2000 2000 2000 2000 2000 2000 2000 2000 2000 2000 2000 2000 2000 2000 2000 2000
				2000 2000 2000 2000 2000 2000 2000 2000 2000 2000 2000 2000 2000 2000 2000 2000 2000 2000
				2000 2000 2000 2000 2000 2000 2000 2000 2000 2000 2000 2000 2000 2000 2000 2000 2000 2000
				2000 2000 2000 2000 2000 2000 2000 2000 2000 2000 2000 2000 2000 2000 2000 2000 2000 2000
				2000 2000 2000>;

			PS_Config_Lmt_FW_Rawdata_N = <
				400 400 400 400 400 400 400 400 400 400 400 400 400 400 400 400 400 400
				400 400 400 400 400 400 400 400 400 400 400 400 400 400 400 400 400 400
				400 400 400 400 400 400 400 400 400 400 400 400 400 400 400 400 400 400
				400 400 400 400 400 400 400 400 400 400 400 400 400 400 400 400 400 400
				400 400 400 400 400 400 400 400 400 400 400 400 400 400 400 400 400 400
				400 400 400 400 400 400 400 400 400 400 400 400 400 400 400 400 400 400
				400 400 400 400 400 400 400 400 400 400 400 400 400 400 400 400 400 400
				400 400 400 400 400 400 400 400 400 400 400 400 400 400 400 400 400 400
				400 400 400 400 400 400 400 400 400 400 400 400 400 400 400 400 400 400
				400 400 400 400 400 400 400 400 400 400 400 400 400 400 400 400 400 400
				400 400 400 400 400 400 400 400 400 400 400 400 400 400 400 400 400 400
				400 400 400 400 400 400 400 400 400 400 400 400 400 400 400 400 400 400
				400 400 400 400 400 400 400 400 400 400 400 400 400 400 400 400 400 400
				400 400 400 400 400 400 400 400 400 400 400 400 400 400 400 400 400 400
				400 400 400 400 400 400 400 400 400 400 400 400 400 400 400 400 400 400
				400 400 400 400 400 400 400 400 400 400 400 400 400 400 400 400 400 400
				400 400 400 400 400 400 400 400 400 400 400 400 400 400 400 400 400 400
				400 400 400 400 400 400 400 400 400 400 400 400 400 400 400 400 400 400
				400 400 400 400 400 400 400 400 400 400 400 400 400 400 400 400 400 400
				400 400 400 400 400 400 400 400 400 400 400 400 400 400 400 400 400 400
				400 400 400 400 400 400 400 400 400 400 400 400 400 400 400 400 400 400
				400 400 400 400 400 400 400 400 400 400 400 400 400 400 400 400 400 400
				400 400 400 400 400 400 400 400 400 400 400 400 400 400 400 400 400 400
				400 400 400 400 400 400 400 400 400 400 400 400 400 400 400 400 400 400
				400 400 400 400 400 400 400 400 400 400 400 400 400 400 400 400 400 400
				400 400 400 400 400 400 400 400 400 400 400 400 400 400 400 400 400 400
				400 400 400 400 400 400 400 400 400 400 400 400 400 400 400 400 400 400
				400 400 400 400 400 400 400 400 400 400 400 400 400 400 400 400 400 400
				400 400 400 400 400 400 400 400 400 400 400 400 400 400 400 400 400 400
				400 400 400 400 400 400 400 400 400 400 400 400 400 400 400 400 400 400
				400 400 400 400 400 400 400 400 400 400 400 400 400 400 400 400 400 400
				400 400 400 400 400 400 400 400 400 400 400 400 400 400 400 400 400 400
				400 400 400>;

			PS_Config_Lmt_FW_CC_P = <
				38 38 38 38 38 38 38 38 38 38 38 38 38 38 38 38 38 38
				38 38 38 38 38 38 38 38 38 38 38 38 38 38 38 38 38 38
				38 38 38 38 38 38 38 38 38 38 38 38 38 38 38 38 38 38
				38 38 38 38 38 38 38 38 38 38 38 38 38 38 38 38 38 38
				38 38 38 38 38 38 38 38 38 38 38 38 38 38 38 38 38 38
				38 38 38 38 38 38 38 38 38 38 38 38 38 38 38 38 38 38
				38 38 38 38 38 38 38 38 38 38 38 38 38 38 38 38 38 38
				38 38 38 38 38 38 38 38 38 38 38 38 38 38 38 38 38 38
				38 38 38 38 38 38 38 38 38 38 38 38 38 38 38 38 38 38
				38 38 38 38 38 38 38 38 38 38 38 38 38 38 38 38 38 38
				38 38 38 38 38 38 38 38 38 38 38 38 38 38 38 38 38 38
				38 38 38 38 38 38 38 38 38 38 38 38 38 38 38 38 38 38
				38 38 38 38 38 38 38 38 38 38 38 38 38 38 38 38 38 38
				38 38 38 38 38 38 38 38 38 38 38 38 38 38 38 38 38 38
				38 38 38 38 38 38 38 38 38 38 38 38 38 38 38 38 38 38
				38 38 38 38 38 38 38 38 38 38 38 38 38 38 38 38 38 38
				38 38 38 38 38 38 38 38 38 38 38 38 38 38 38 38 38 38
				38 38 38 38 38 38 38 38 38 38 38 38 38 38 38 38 38 38
				38 38 38 38 38 38 38 38 38 38 38 38 38 38 38 38 38 38
				38 38 38 38 38 38 38 38 38 38 38 38 38 38 38 38 38 38
				38 38 38 38 38 38 38 38 38 38 38 38 38 38 38 38 38 38
				38 38 38 38 38 38 38 38 38 38 38 38 38 38 38 38 38 38
				38 38 38 38 38 38 38 38 38 38 38 38 38 38 38 38 38 38
				38 38 38 38 38 38 38 38 38 38 38 38 38 38 38 38 38 38
				38 38 38 38 38 38 38 38 38 38 38 38 38 38 38 38 38 38
				38 38 38 38 38 38 38 38 38 38 38 38 38 38 38 38 38 38
				38 38 38 38 38 38 38 38 38 38 38 38 38 38 38 38 38 38
				38 38 38 38 38 38 38 38 38 38 38 38 38 38 38 38 38 38
				38 38 38 38 38 38 38 38 38 38 38 38 38 38 38 38 38 38
				38 38 38 38 38 38 38 38 38 38 38 38 38 38 38 38 38 38
				38 38 38 38 38 38 38 38 38 38 38 38 38 38 38 38 38 38
				38 38 38 38 38 38 38 38 38 38 38 38 38 38 38 38 38 38
				38 38 38>;

			PS_Config_Lmt_FW_CC_N = <
				9 9 9 9 9 9 9 9 9 9 9 9 9 9 9 9 9 9
				9 9 9 9 9 9 9 9 9 9 9 9 9 9 9 9 9 9
				9 9 9 9 9 9 9 9 9 9 9 9 9 9 9 9 9 9
				9 9 9 9 9 9 9 9 9 9 9 9 9 9 9 9 9 9
				9 9 9 9 9 9 9 9 9 9 9 9 9 9 9 9 9 9
				9 9 9 9 9 9 9 9 9 9 9 9 9 9 9 9 9 9
				9 9 9 9 9 9 9 9 9 9 9 9 9 9 9 9 9 9
				9 9 9 9 9 9 9 9 9 9 9 9 9 9 9 9 9 9
				9 9 9 9 9 9 9 9 9 9 9 9 9 9 9 9 9 9
				9 9 9 9 9 9 9 9 9 9 9 9 9 9 9 9 9 9
				9 9 9 9 9 9 9 9 9 9 9 9 9 9 9 9 9 9
				9 9 9 9 9 9 9 9 9 9 9 9 9 9 9 9 9 9
				9 9 9 9 9 9 9 9 9 9 9 9 9 9 9 9 9 9
				9 9 9 9 9 9 9 9 9 9 9 9 9 9 9 9 9 9
				9 9 9 9 9 9 9 9 9 9 9 9 9 9 9 9 9 9
				9 9 9 9 9 9 9 9 9 9 9 9 9 9 9 9 9 9
				9 9 9 9 9 9 9 9 9 9 9 9 9 9 9 9 9 9
				9 9 9 9 9 9 9 9 9 9 9 9 9 9 9 9 9 9
				9 9 9 9 9 9 9 9 9 9 9 9 9 9 9 9 9 9
				9 9 9 9 9 9 9 9 9 9 9 9 9 9 9 9 9 9
				9 9 9 9 9 9 9 9 9 9 9 9 9 9 9 9 9 9
				9 9 9 9 9 9 9 9 9 9 9 9 9 9 9 9 9 9
				9 9 9 9 9 9 9 9 9 9 9 9 9 9 9 9 9 9
				9 9 9 9 9 9 9 9 9 9 9 9 9 9 9 9 9 9
				9 9 9 9 9 9 9 9 9 9 9 9 9 9 9 9 9 9
				9 9 9 9 9 9 9 9 9 9 9 9 9 9 9 9 9 9
				9 9 9 9 9 9 9 9 9 9 9 9 9 9 9 9 9 9
				9 9 9 9 9 9 9 9 9 9 9 9 9 9 9 9 9 9
				9 9 9 9 9 9 9 9 9 9 9 9 9 9 9 9 9 9
				9 9 9 9 9 9 9 9 9 9 9 9 9 9 9 9 9 9
				9 9 9 9 9 9 9 9 9 9 9 9 9 9 9 9 9 9
				9 9 9 9 9 9 9 9 9 9 9 9 9 9 9 9 9 9
				9 9 9>;

			PS_Config_Lmt_FW_CC_I_P = <
				25 25 25 25 25 25 25 25 25 25 25 25 25 25 25 25 25 25
				25 25 25 25 25 25 25 25 25 25 25 25 25 25 25 25 25 25
				25 25 25 25 25 25 25 25 25 25 25 25 25 25 25 25 25 25
				25 25 25 25 25 25 25 25 25 25 25 25 25 25 25 25 25 25
				25 25 25 25 25 25 25 25 25 25 25 25 25 25 25 25 25 25
				25 25 25 25 25 25 25 25 25 25 25 25 25 25 25 25 25 25
				25 25 25 25 25 25 25 25 25 25 25 25 25 25 25 25 25 25
				25 25 25 25 25 25 25 25 25 25 25 25 25 25 25 25 25 25
				25 25 25 25 25 25 25 25 25 25 25 25 25 25 25 25 25 25
				25 25 25 25 25 25 25 25 25 25 25 25 25 25 25 25 25 25
				25 25 25 25 25 25 25 25 25 25 25 25 25 25 25 25 25 25
				25 25 25 25 25 25 25 25 25 25 25 25 25 25 25 25 25 25
				25 25 25 25 25 25 25 25 25 25 25 25 25 25 25 25 25 25
				25 25 25 25 25 25 25 25 25 25 25 25 25 25 25 25 25 25
				25 25 25 25 25 25 25 25 25 25 25 25 25 25 25 25 25 25
				25 25 25 25 25 25 25 25 25 25 25 25 25 25 25 25 25 25
				25 25 25 25 25 25 25 25 25 25 25 25 25 25 25 25 25 25
				25 25 25 25 25 25 25 25 25 25 25 25 25 25 25 25 25 25
				25 25 25 25 25 25 25 25 25 25 25 25 25 25 25 25 25 25
				25 25 25 25 25 25 25 25 25 25 25 25 25 25 25 25 25 25
				25 25 25 25 25 25 25 25 25 25 25 25 25 25 25 25 25 25
				25 25 25 25 25 25 25 25 25 25 25 25 25 25 25 25 25 25
				25 25 25 25 25 25 25 25 25 25 25 25 25 25 25 25 25 25
				25 25 25 25 25 25 25 25 25 25 25 25 25 25 25 25 25 25
				25 25 25 25 25 25 25 25 25 25 25 25 25 25 25 25 25 25
				25 25 25 25 25 25 25 25 25 25 25 25 25 25 25 25 25 25
				25 25 25 25 25 25 25 25 25 25 25 25 25 25 25 25 25 25
				25 25 25 25 25 25 25 25 25 25 25 25 25 25 25 25 25 25
				25 25 25 25 25 25 25 25 25 25 25 25 25 25 25 25 25 25
				25 25 25 25 25 25 25 25 25 25 25 25 25 25 25 25 25 25
				25 25 25 25 25 25 25 25 25 25 25 25 25 25 25 25 25 25
				25 25 25 25 25 25 25 25 25 25 25 25 25 25 25 25 25 25
				25 25 25>;

			PS_Config_Lmt_FW_CC_I_N = <
				0 0 0 0 0 0 0 0 0 0 0 0 0 0 0 0 0 0
				0 0 0 0 0 0 0 0 0 0 0 0 0 0 0 0 0 0
				0 0 0 0 0 0 0 0 0 0 0 0 0 0 0 0 0 0
				0 0 0 0 0 0 0 0 0 0 0 0 0 0 0 0 0 0
				0 0 0 0 0 0 0 0 0 0 0 0 0 0 0 0 0 0
				0 0 0 0 0 0 0 0 0 0 0 0 0 0 0 0 0 0
				0 0 0 0 0 0 0 0 0 0 0 0 0 0 0 0 0 0
				0 0 0 0 0 0 0 0 0 0 0 0 0 0 0 0 0 0
				0 0 0 0 0 0 0 0 0 0 0 0 0 0 0 0 0 0
				0 0 0 0 0 0 0 0 0 0 0 0 0 0 0 0 0 0
				0 0 0 0 0 0 0 0 0 0 0 0 0 0 0 0 0 0
				0 0 0 0 0 0 0 0 0 0 0 0 0 0 0 0 0 0
				0 0 0 0 0 0 0 0 0 0 0 0 0 0 0 0 0 0
				0 0 0 0 0 0 0 0 0 0 0 0 0 0 0 0 0 0
				0 0 0 0 0 0 0 0 0 0 0 0 0 0 0 0 0 0
				0 0 0 0 0 0 0 0 0 0 0 0 0 0 0 0 0 0
				0 0 0 0 0 0 0 0 0 0 0 0 0 0 0 0 0 0
				0 0 0 0 0 0 0 0 0 0 0 0 0 0 0 0 0 0
				0 0 0 0 0 0 0 0 0 0 0 0 0 0 0 0 0 0
				0 0 0 0 0 0 0 0 0 0 0 0 0 0 0 0 0 0
				0 0 0 0 0 0 0 0 0 0 0 0 0 0 0 0 0 0
				0 0 0 0 0 0 0 0 0 0 0 0 0 0 0 0 0 0
				0 0 0 0 0 0 0 0 0 0 0 0 0 0 0 0 0 0
				0 0 0 0 0 0 0 0 0 0 0 0 0 0 0 0 0 0
				0 0 0 0 0 0 0 0 0 0 0 0 0 0 0 0 0 0
				0 0 0 0 0 0 0 0 0 0 0 0 0 0 0 0 0 0
				0 0 0 0 0 0 0 0 0 0 0 0 0 0 0 0 0 0
				0 0 0 0 0 0 0 0 0 0 0 0 0 0 0 0 0 0
				0 0 0 0 0 0 0 0 0 0 0 0 0 0 0 0 0 0
				0 0 0 0 0 0 0 0 0 0 0 0 0 0 0 0 0 0
				0 0 0 0 0 0 0 0 0 0 0 0 0 0 0 0 0 0
				0 0 0 0 0 0 0 0 0 0 0 0 0 0 0 0 0 0
				0 0 0>;

			PS_Config_Lmt_FW_CC_Q_P = <
				25 25 25 25 25 25 25 25 25 25 25 25 25 25 25 25 25 25
				25 25 25 25 25 25 25 25 25 25 25 25 25 25 25 25 25 25
				25 25 25 25 25 25 25 25 25 25 25 25 25 25 25 25 25 25
				25 25 25 25 25 25 25 25 25 25 25 25 25 25 25 25 25 25
				25 25 25 25 25 25 25 25 25 25 25 25 25 25 25 25 25 25
				25 25 25 25 25 25 25 25 25 25 25 25 25 25 25 25 25 25
				25 25 25 25 25 25 25 25 25 25 25 25 25 25 25 25 25 25
				25 25 25 25 25 25 25 25 25 25 25 25 25 25 25 25 25 25
				25 25 25 25 25 25 25 25 25 25 25 25 25 25 25 25 25 25
				25 25 25 25 25 25 25 25 25 25 25 25 25 25 25 25 25 25
				25 25 25 25 25 25 25 25 25 25 25 25 25 25 25 25 25 25
				25 25 25 25 25 25 25 25 25 25 25 25 25 25 25 25 25 25
				25 25 25 25 25 25 25 25 25 25 25 25 25 25 25 25 25 25
				25 25 25 25 25 25 25 25 25 25 25 25 25 25 25 25 25 25
				25 25 25 25 25 25 25 25 25 25 25 25 25 25 25 25 25 25
				25 25 25 25 25 25 25 25 25 25 25 25 25 25 25 25 25 25
				25 25 25 25 25 25 25 25 25 25 25 25 25 25 25 25 25 25
				25 25 25 25 25 25 25 25 25 25 25 25 25 25 25 25 25 25
				25 25 25 25 25 25 25 25 25 25 25 25 25 25 25 25 25 25
				25 25 25 25 25 25 25 25 25 25 25 25 25 25 25 25 25 25
				25 25 25 25 25 25 25 25 25 25 25 25 25 25 25 25 25 25
				25 25 25 25 25 25 25 25 25 25 25 25 25 25 25 25 25 25
				25 25 25 25 25 25 25 25 25 25 25 25 25 25 25 25 25 25
				25 25 25 25 25 25 25 25 25 25 25 25 25 25 25 25 25 25
				25 25 25 25 25 25 25 25 25 25 25 25 25 25 25 25 25 25
				25 25 25 25 25 25 25 25 25 25 25 25 25 25 25 25 25 25
				25 25 25 25 25 25 25 25 25 25 25 25 25 25 25 25 25 25
				25 25 25 25 25 25 25 25 25 25 25 25 25 25 25 25 25 25
				25 25 25 25 25 25 25 25 25 25 25 25 25 25 25 25 25 25
				25 25 25 25 25 25 25 25 25 25 25 25 25 25 25 25 25 25
				25 25 25 25 25 25 25 25 25 25 25 25 25 25 25 25 25 25
				25 25 25 25 25 25 25 25 25 25 25 25 25 25 25 25 25 25
				25 25 25>;

			PS_Config_Lmt_FW_CC_Q_N = <
				0 0 0 0 0 0 0 0 0 0 0 0 0 0 0 0 0 0
				0 0 0 0 0 0 0 0 0 0 0 0 0 0 0 0 0 0
				0 0 0 0 0 0 0 0 0 0 0 0 0 0 0 0 0 0
				0 0 0 0 0 0 0 0 0 0 0 0 0 0 0 0 0 0
				0 0 0 0 0 0 0 0 0 0 0 0 0 0 0 0 0 0
				0 0 0 0 0 0 0 0 0 0 0 0 0 0 0 0 0 0
				0 0 0 0 0 0 0 0 0 0 0 0 0 0 0 0 0 0
				0 0 0 0 0 0 0 0 0 0 0 0 0 0 0 0 0 0
				0 0 0 0 0 0 0 0 0 0 0 0 0 0 0 0 0 0
				0 0 0 0 0 0 0 0 0 0 0 0 0 0 0 0 0 0
				0 0 0 0 0 0 0 0 0 0 0 0 0 0 0 0 0 0
				0 0 0 0 0 0 0 0 0 0 0 0 0 0 0 0 0 0
				0 0 0 0 0 0 0 0 0 0 0 0 0 0 0 0 0 0
				0 0 0 0 0 0 0 0 0 0 0 0 0 0 0 0 0 0
				0 0 0 0 0 0 0 0 0 0 0 0 0 0 0 0 0 0
				0 0 0 0 0 0 0 0 0 0 0 0 0 0 0 0 0 0
				0 0 0 0 0 0 0 0 0 0 0 0 0 0 0 0 0 0
				0 0 0 0 0 0 0 0 0 0 0 0 0 0 0 0 0 0
				0 0 0 0 0 0 0 0 0 0 0 0 0 0 0 0 0 0
				0 0 0 0 0 0 0 0 0 0 0 0 0 0 0 0 0 0
				0 0 0 0 0 0 0 0 0 0 0 0 0 0 0 0 0 0
				0 0 0 0 0 0 0 0 0 0 0 0 0 0 0 0 0 0
				0 0 0 0 0 0 0 0 0 0 0 0 0 0 0 0 0 0
				0 0 0 0 0 0 0 0 0 0 0 0 0 0 0 0 0 0
				0 0 0 0 0 0 0 0 0 0 0 0 0 0 0 0 0 0
				0 0 0 0 0 0 0 0 0 0 0 0 0 0 0 0 0 0
				0 0 0 0 0 0 0 0 0 0 0 0 0 0 0 0 0 0
				0 0 0 0 0 0 0 0 0 0 0 0 0 0 0 0 0 0
				0 0 0 0 0 0 0 0 0 0 0 0 0 0 0 0 0 0
				0 0 0 0 0 0 0 0 0 0 0 0 0 0 0 0 0 0
				0 0 0 0 0 0 0 0 0 0 0 0 0 0 0 0 0 0
				0 0 0 0 0 0 0 0 0 0 0 0 0 0 0 0 0 0
				0 0 0>;

			PS_Config_Lmt_FW_Diff_P = <
				35 35 35 35 35 35 35 35 35 35 35 35 35 35 35 35 35 35
				35 35 35 35 35 35 35 35 35 35 35 35 35 35 35 35 35 35
				35 35 35 35 35 35 35 35 35 35 35 35 35 35 35 35 35 35
				35 35 35 35 35 35 35 35 35 35 35 35 35 35 35 35 35 35
				35 35 35 35 35 35 35 35 35 35 35 35 35 35 35 35 35 35
				35 35 35 35 35 35 35 35 35 35 35 35 35 35 35 35 35 35
				35 35 35 35 35 35 35 35 35 35 35 35 35 35 35 35 35 35
				35 35 35 35 35 35 35 35 35 35 35 35 35 35 35 35 35 35
				35 35 35 35 35 35 35 35 35 35 35 35 35 35 35 35 35 35
				35 35 35 35 35 35 35 35 35 35 35 35 35 35 35 35 35 35
				35 35 35 35 35 35 35 35 35 35 35 35 35 35 35 35 35 35
				35 35 35 35 35 35 35 35 35 35 35 35 35 35 35 35 35 35
				35 35 35 35 35 35 35 35 35 35 35 35 35 35 35 35 35 35
				35 35 35 35 35 35 35 35 35 35 35 35 35 35 35 35 35 35
				35 35 35 35 35 35 35 35 35 35 35 35 35 35 35 35 35 35
				35 35 35 35 35 35 35 35 35 35 35 35 35 35 35 35 35 35
				35 35 35 35 35 35 35 35 35 35 35 35 35 35 35 35 35 35
				35 35 35 35 35 35 35 35 35 35 35 35 35 35 35 35 35 35
				35 35 35 35 35 35 35 35 35 35 35 35 35 35 35 35 35 35
				35 35 35 35 35 35 35 35 35 35 35 35 35 35 35 35 35 35
				35 35 35 35 35 35 35 35 35 35 35 35 35 35 35 35 35 35
				35 35 35 35 35 35 35 35 35 35 35 35 35 35 35 35 35 35
				35 35 35 35 35 35 35 35 35 35 35 35 35 35 35 35 35 35
				35 35 35 35 35 35 35 35 35 35 35 35 35 35 35 35 35 35
				35 35 35 35 35 35 35 35 35 35 35 35 35 35 35 35 35 35
				35 35 35 35 35 35 35 35 35 35 35 35 35 35 35 35 35 35
				35 35 35 35 35 35 35 35 35 35 35 35 35 35 35 35 35 35
				35 35 35 35 35 35 35 35 35 35 35 35 35 35 35 35 35 35
				35 35 35 35 35 35 35 35 35 35 35 35 35 35 35 35 35 35
				35 35 35 35 35 35 35 35 35 35 35 35 35 35 35 35 35 35
				35 35 35 35 35 35 35 35 35 35 35 35 35 35 35 35 35 35
				35 35 35 35 35 35 35 35 35 35 35 35 35 35 35 35 35 35
				35 35 35>;

			PS_Config_Lmt_FW_Diff_N = <
				0xffffffdd 0xffffffdd 0xffffffdd 0xffffffdd 0xffffffdd 0xffffffdd 0xffffffdd 0xffffffdd 0xffffffdd 0xffffffdd 0xffffffdd 0xffffffdd 0xffffffdd 0xffffffdd 0xffffffdd 0xffffffdd 0xffffffdd 0xffffffdd
				0xffffffdd 0xffffffdd 0xffffffdd 0xffffffdd 0xffffffdd 0xffffffdd 0xffffffdd 0xffffffdd 0xffffffdd 0xffffffdd 0xffffffdd 0xffffffdd 0xffffffdd 0xffffffdd 0xffffffdd 0xffffffdd 0xffffffdd 0xffffffdd
				0xffffffdd 0xffffffdd 0xffffffdd 0xffffffdd 0xffffffdd 0xffffffdd 0xffffffdd 0xffffffdd 0xffffffdd 0xffffffdd 0xffffffdd 0xffffffdd 0xffffffdd 0xffffffdd 0xffffffdd 0xffffffdd 0xffffffdd 0xffffffdd
				0xffffffdd 0xffffffdd 0xffffffdd 0xffffffdd 0xffffffdd 0xffffffdd 0xffffffdd 0xffffffdd 0xffffffdd 0xffffffdd 0xffffffdd 0xffffffdd 0xffffffdd 0xffffffdd 0xffffffdd 0xffffffdd 0xffffffdd 0xffffffdd
				0xffffffdd 0xffffffdd 0xffffffdd 0xffffffdd 0xffffffdd 0xffffffdd 0xffffffdd 0xffffffdd 0xffffffdd 0xffffffdd 0xffffffdd 0xffffffdd 0xffffffdd 0xffffffdd 0xffffffdd 0xffffffdd 0xffffffdd 0xffffffdd
				0xffffffdd 0xffffffdd 0xffffffdd 0xffffffdd 0xffffffdd 0xffffffdd 0xffffffdd 0xffffffdd 0xffffffdd 0xffffffdd 0xffffffdd 0xffffffdd 0xffffffdd 0xffffffdd 0xffffffdd 0xffffffdd 0xffffffdd 0xffffffdd
				0xffffffdd 0xffffffdd 0xffffffdd 0xffffffdd 0xffffffdd 0xffffffdd 0xffffffdd 0xffffffdd 0xffffffdd 0xffffffdd 0xffffffdd 0xffffffdd 0xffffffdd 0xffffffdd 0xffffffdd 0xffffffdd 0xffffffdd 0xffffffdd
				0xffffffdd 0xffffffdd 0xffffffdd 0xffffffdd 0xffffffdd 0xffffffdd 0xffffffdd 0xffffffdd 0xffffffdd 0xffffffdd 0xffffffdd 0xffffffdd 0xffffffdd 0xffffffdd 0xffffffdd 0xffffffdd 0xffffffdd 0xffffffdd
				0xffffffdd 0xffffffdd 0xffffffdd 0xffffffdd 0xffffffdd 0xffffffdd 0xffffffdd 0xffffffdd 0xffffffdd 0xffffffdd 0xffffffdd 0xffffffdd 0xffffffdd 0xffffffdd 0xffffffdd 0xffffffdd 0xffffffdd 0xffffffdd
				0xffffffdd 0xffffffdd 0xffffffdd 0xffffffdd 0xffffffdd 0xffffffdd 0xffffffdd 0xffffffdd 0xffffffdd 0xffffffdd 0xffffffdd 0xffffffdd 0xffffffdd 0xffffffdd 0xffffffdd 0xffffffdd 0xffffffdd 0xffffffdd
				0xffffffdd 0xffffffdd 0xffffffdd 0xffffffdd 0xffffffdd 0xffffffdd 0xffffffdd 0xffffffdd 0xffffffdd 0xffffffdd 0xffffffdd 0xffffffdd 0xffffffdd 0xffffffdd 0xffffffdd 0xffffffdd 0xffffffdd 0xffffffdd
				0xffffffdd 0xffffffdd 0xffffffdd 0xffffffdd 0xffffffdd 0xffffffdd 0xffffffdd 0xffffffdd 0xffffffdd 0xffffffdd 0xffffffdd 0xffffffdd 0xffffffdd 0xffffffdd 0xffffffdd 0xffffffdd 0xffffffdd 0xffffffdd
				0xffffffdd 0xffffffdd 0xffffffdd 0xffffffdd 0xffffffdd 0xffffffdd 0xffffffdd 0xffffffdd 0xffffffdd 0xffffffdd 0xffffffdd 0xffffffdd 0xffffffdd 0xffffffdd 0xffffffdd 0xffffffdd 0xffffffdd 0xffffffdd
				0xffffffdd 0xffffffdd 0xffffffdd 0xffffffdd 0xffffffdd 0xffffffdd 0xffffffdd 0xffffffdd 0xffffffdd 0xffffffdd 0xffffffdd 0xffffffdd 0xffffffdd 0xffffffdd 0xffffffdd 0xffffffdd 0xffffffdd 0xffffffdd
				0xffffffdd 0xffffffdd 0xffffffdd 0xffffffdd 0xffffffdd 0xffffffdd 0xffffffdd 0xffffffdd 0xffffffdd 0xffffffdd 0xffffffdd 0xffffffdd 0xffffffdd 0xffffffdd 0xffffffdd 0xffffffdd 0xffffffdd 0xffffffdd
				0xffffffdd 0xffffffdd 0xffffffdd 0xffffffdd 0xffffffdd 0xffffffdd 0xffffffdd 0xffffffdd 0xffffffdd 0xffffffdd 0xffffffdd 0xffffffdd 0xffffffdd 0xffffffdd 0xffffffdd 0xffffffdd 0xffffffdd 0xffffffdd
				0xffffffdd 0xffffffdd 0xffffffdd 0xffffffdd 0xffffffdd 0xffffffdd 0xffffffdd 0xffffffdd 0xffffffdd 0xffffffdd 0xffffffdd 0xffffffdd 0xffffffdd 0xffffffdd 0xffffffdd 0xffffffdd 0xffffffdd 0xffffffdd
				0xffffffdd 0xffffffdd 0xffffffdd 0xffffffdd 0xffffffdd 0xffffffdd 0xffffffdd 0xffffffdd 0xffffffdd 0xffffffdd 0xffffffdd 0xffffffdd 0xffffffdd 0xffffffdd 0xffffffdd 0xffffffdd 0xffffffdd 0xffffffdd
				0xffffffdd 0xffffffdd 0xffffffdd 0xffffffdd 0xffffffdd 0xffffffdd 0xffffffdd 0xffffffdd 0xffffffdd 0xffffffdd 0xffffffdd 0xffffffdd 0xffffffdd 0xffffffdd 0xffffffdd 0xffffffdd 0xffffffdd 0xffffffdd
				0xffffffdd 0xffffffdd 0xffffffdd 0xffffffdd 0xffffffdd 0xffffffdd 0xffffffdd 0xffffffdd 0xffffffdd 0xffffffdd 0xffffffdd 0xffffffdd 0xffffffdd 0xffffffdd 0xffffffdd 0xffffffdd 0xffffffdd 0xffffffdd
				0xffffffdd 0xffffffdd 0xffffffdd 0xffffffdd 0xffffffdd 0xffffffdd 0xffffffdd 0xffffffdd 0xffffffdd 0xffffffdd 0xffffffdd 0xffffffdd 0xffffffdd 0xffffffdd 0xffffffdd 0xffffffdd 0xffffffdd 0xffffffdd
				0xffffffdd 0xffffffdd 0xffffffdd 0xffffffdd 0xffffffdd 0xffffffdd 0xffffffdd 0xffffffdd 0xffffffdd 0xffffffdd 0xffffffdd 0xffffffdd 0xffffffdd 0xffffffdd 0xffffffdd 0xffffffdd 0xffffffdd 0xffffffdd
				0xffffffdd 0xffffffdd 0xffffffdd 0xffffffdd 0xffffffdd 0xffffffdd 0xffffffdd 0xffffffdd 0xffffffdd 0xffffffdd 0xffffffdd 0xffffffdd 0xffffffdd 0xffffffdd 0xffffffdd 0xffffffdd 0xffffffdd 0xffffffdd
				0xffffffdd 0xffffffdd 0xffffffdd 0xffffffdd 0xffffffdd 0xffffffdd 0xffffffdd 0xffffffdd 0xffffffdd 0xffffffdd 0xffffffdd 0xffffffdd 0xffffffdd 0xffffffdd 0xffffffdd 0xffffffdd 0xffffffdd 0xffffffdd
				0xffffffdd 0xffffffdd 0xffffffdd 0xffffffdd 0xffffffdd 0xffffffdd 0xffffffdd 0xffffffdd 0xffffffdd 0xffffffdd 0xffffffdd 0xffffffdd 0xffffffdd 0xffffffdd 0xffffffdd 0xffffffdd 0xffffffdd 0xffffffdd
				0xffffffdd 0xffffffdd 0xffffffdd 0xffffffdd 0xffffffdd 0xffffffdd 0xffffffdd 0xffffffdd 0xffffffdd 0xffffffdd 0xffffffdd 0xffffffdd 0xffffffdd 0xffffffdd 0xffffffdd 0xffffffdd 0xffffffdd 0xffffffdd
				0xffffffdd 0xffffffdd 0xffffffdd 0xffffffdd 0xffffffdd 0xffffffdd 0xffffffdd 0xffffffdd 0xffffffdd 0xffffffdd 0xffffffdd 0xffffffdd 0xffffffdd 0xffffffdd 0xffffffdd 0xffffffdd 0xffffffdd 0xffffffdd
				0xffffffdd 0xffffffdd 0xffffffdd 0xffffffdd 0xffffffdd 0xffffffdd 0xffffffdd 0xffffffdd 0xffffffdd 0xffffffdd 0xffffffdd 0xffffffdd 0xffffffdd 0xffffffdd 0xffffffdd 0xffffffdd 0xffffffdd 0xffffffdd
				0xffffffdd 0xffffffdd 0xffffffdd 0xffffffdd 0xffffffdd 0xffffffdd 0xffffffdd 0xffffffdd 0xffffffdd 0xffffffdd 0xffffffdd 0xffffffdd 0xffffffdd 0xffffffdd 0xffffffdd 0xffffffdd 0xffffffdd 0xffffffdd
				0xffffffdd 0xffffffdd 0xffffffdd 0xffffffdd 0xffffffdd 0xffffffdd 0xffffffdd 0xffffffdd 0xffffffdd 0xffffffdd 0xffffffdd 0xffffffdd 0xffffffdd 0xffffffdd 0xffffffdd 0xffffffdd 0xffffffdd 0xffffffdd
				0xffffffdd 0xffffffdd 0xffffffdd 0xffffffdd 0xffffffdd 0xffffffdd 0xffffffdd 0xffffffdd 0xffffffdd 0xffffffdd 0xffffffdd 0xffffffdd 0xffffffdd 0xffffffdd 0xffffffdd 0xffffffdd 0xffffffdd 0xffffffdd
				0xffffffdd 0xffffffdd 0xffffffdd 0xffffffdd 0xffffffdd 0xffffffdd 0xffffffdd 0xffffffdd 0xffffffdd 0xffffffdd 0xffffffdd 0xffffffdd 0xffffffdd 0xffffffdd 0xffffffdd 0xffffffdd 0xffffffdd 0xffffffdd
				0xffffffdd 0xffffffdd 0xffffffdd>;

			PS_Config_Diff_Test_Frame = <50>;
		};
	};

	solomon@53 {
		compatible = "solomon,ssd20xx";
		reg = <0x53>;
		interrupt-parent = <&tlmm>;
		interrupts = <67 0x2008>;
		vcc-i2c-supply = <&pm660_l11>;
		pinctrl-names = "pmx_ts_active","pmx_ts_suspend";
		pinctrl-0 = <&ts_active>;
		pinctrl-1 = <&ts_int_suspend &ts_reset_suspend>;
		reset-gpios = <&tlmm 66 0x00>;
		interrupt-gpios = <&tlmm 67 0x00>;
		solomon,button-map = <139 172 158>;
		solomon,panel-coords = <0 0 1080 2160>;
		solomon,display-coords = <0 0 1080 2160>;
		solomon,product-id = "ssd20xx";
		solomon,fw_name = "str_fw.img";
		solomon,i2c-pull-up;
	};
};
